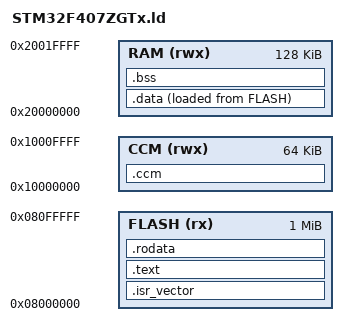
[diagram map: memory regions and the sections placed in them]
/* Linker script for STM32F407ZGT6 — 1MB Flash, 128KB SRAM + 64KB CCM */
MEMORY
{
  FLASH (rx)  : ORIGIN = 0x08000000, LENGTH = 1024K
  RAM   (rwx) : ORIGIN = 0x20000000, LENGTH = 128K
  CCM   (rwx) : ORIGIN = 0x10000000, LENGTH = 64K
}

_estack = ORIGIN(RAM) + LENGTH(RAM);

SECTIONS
{
  .isr_vector :
  {
    . = ALIGN(4);
    KEEP(*(.isr_vector))
    . = ALIGN(4);
  } >FLASH

  .text :
  {
    . = ALIGN(4);
    *(.text)
    *(.text*)
    *(.glue_7)
    *(.glue_7t)
    *(.eh_frame)
    KEEP(*(.init))
    KEEP(*(.fini))
    . = ALIGN(4);
  } >FLASH

  .rodata :
  {
    . = ALIGN(4);
    *(.rodata)
    *(.rodata*)
    . = ALIGN(4);
  } >FLASH

  _sidata = LOADADDR(.data);
  .data :
  {
    . = ALIGN(4);
    _sdata = .;
    *(.data)
    *(.data*)
    . = ALIGN(4);
    _edata = .;
  } >RAM AT>FLASH

  .bss :
  {
    . = ALIGN(4);
    _sbss = .;
    *(.bss)
    *(.bss*)
    *(COMMON)
    . = ALIGN(4);
    _ebss = .;
    end = .;
  } >RAM

  .ccm (NOLOAD) :
  {
    . = ALIGN(4);
    *(.ccm)
    *(.ccm*)
    . = ALIGN(4);
  } >CCM
}
